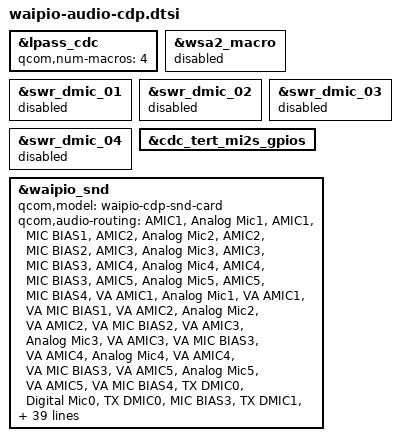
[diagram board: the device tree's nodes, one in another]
#include "waipio-audio-overlay.dtsi"

&lpass_cdc {
	qcom,num-macros = <4>;
};

&wsa2_macro {
	status = "disabled";
};

&swr_dmic_01 {
	status = "disabled";
};

&swr_dmic_02 {
	status = "disabled";
};

&swr_dmic_03 {
	status = "disabled";
};

&swr_dmic_04 {
	status = "disabled";
};

&cdc_tert_mi2s_gpios {
	status = "ok";
};

&waipio_snd {
	qcom,model = "waipio-cdp-snd-card";
	qcom,audio-routing =
		"AMIC1", "Analog Mic1",
		"AMIC1", "MIC BIAS1",
		"AMIC2", "Analog Mic2",
		"AMIC2", "MIC BIAS2",
		"AMIC3", "Analog Mic3",
		"AMIC3", "MIC BIAS3",
		"AMIC4", "Analog Mic4",
		"AMIC4", "MIC BIAS3",
		"AMIC5", "Analog Mic5",
		"AMIC5", "MIC BIAS4",
		"VA AMIC1", "Analog Mic1",
		"VA AMIC1", "VA MIC BIAS1",
		"VA AMIC2", "Analog Mic2",
		"VA AMIC2", "VA MIC BIAS2",
		"VA AMIC3", "Analog Mic3",
		"VA AMIC3", "VA MIC BIAS3",
		"VA AMIC4", "Analog Mic4",
		"VA AMIC4", "VA MIC BIAS3",
		"VA AMIC5", "Analog Mic5",
		"VA AMIC5", "VA MIC BIAS4",
		"TX DMIC0", "Digital Mic0",
		"TX DMIC0", "MIC BIAS3",
		"TX DMIC1", "Digital Mic1",
		"TX DMIC1", "MIC BIAS3",
		"TX DMIC2", "Digital Mic2",
		"TX DMIC2", "MIC BIAS1",
		"TX DMIC3", "Digital Mic3",
		"TX DMIC3", "MIC BIAS1",
		"TX DMIC4", "Digital Mic4",
		"TX DMIC4", "MIC BIAS4",
		"TX DMIC5", "Digital Mic5",
		"TX DMIC5", "MIC BIAS4",
		"TX DMIC6", "Digital Mic6",
		"TX DMIC6", "MIC BIAS3",
		"TX DMIC7", "Digital Mic7",
		"TX DMIC7", "MIC BIAS3",
		"IN1_HPHL", "HPHL_OUT",
		"IN2_HPHR", "HPHR_OUT",
		"IN3_AUX", "AUX_OUT",
		"HAP_IN", "PCM_OUT",
		"WSA SRC0_INP", "SRC0",
		"WSA_TX DEC0_INP", "TX DEC0 MUX",
		"WSA_TX DEC1_INP", "TX DEC1 MUX",
		"RX_TX DEC0_INP", "TX DEC0 MUX",
		"RX_TX DEC1_INP", "TX DEC1 MUX",
		"RX_TX DEC2_INP", "TX DEC2 MUX",
		"RX_TX DEC3_INP", "TX DEC3 MUX",
		"SpkrLeft IN", "WSA_SPK1 OUT",
		"SpkrRight IN", "WSA_SPK2 OUT",
		"TX SWR_INPUT", "WCD_TX_OUTPUT",
		"VA SWR_INPUT", "VA_SWR_CLK",
		"VA SWR_INPUT", "WCD_TX_OUTPUT",
		"VA_AIF1 CAP", "VA_SWR_CLK",
		"VA_AIF2 CAP", "VA_SWR_CLK",
		"VA_AIF3 CAP", "VA_SWR_CLK",
		"VA DMIC0", "Digital Mic0",
		"VA DMIC1", "Digital Mic1",
		"VA DMIC2", "Digital Mic2",
		"VA DMIC3", "Digital Mic3",
		"VA DMIC4", "Digital Mic4",
		"VA DMIC5", "Digital Mic5",
		"VA DMIC6", "Digital Mic6",
		"VA DMIC7", "Digital Mic7",
		"VA DMIC0", "VA MIC BIAS3",
		"VA DMIC1", "VA MIC BIAS3",
		"VA DMIC2", "VA MIC BIAS1",
		"VA DMIC3", "VA MIC BIAS1",
		"VA DMIC4", "VA MIC BIAS4",
		"VA DMIC5", "VA MIC BIAS4",
		"VA DMIC6", "VA MIC BIAS3",
		"VA DMIC7", "VA MIC BIAS3";
	qcom,cdc-dmic67-gpios = <&cdc_dmic67_gpios>;
	asoc-codec  = <&stub_codec>, <&lpass_cdc>,
			<&wcd938x_codec>, <&swr_haptics>,
			<&wsa883x_0221>, <&wsa883x_0222>;
	asoc-codec-names = "msm-stub-codec.1", "lpass-cdc",
			"wcd938x_codec", "swr-haptics",
			"wsa-codec1", "wsa-codec2";
	qcom,wsa-max-devs = <2>;

	qcom,tert-mi2s-gpios = <&cdc_tert_mi2s_gpios>;
};

